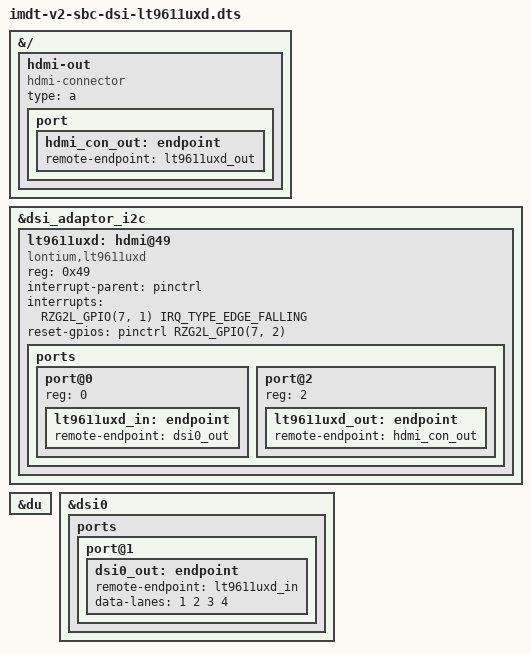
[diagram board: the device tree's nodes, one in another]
/dts-v1/;
/plugin/;

#include <dt-bindings/interrupt-controller/arm-gic.h>
#include <dt-bindings/pinctrl/rzg2l-pinctrl.h>
#include <dt-bindings/gpio/gpio.h>

&{/} {
	hdmi-out {
		compatible = "hdmi-connector";
		type = "a";

		port {
			hdmi_con_out: endpoint {
				remote-endpoint = <&lt9611uxd_out>;
			};
		};
	};
};

&dsi_adaptor_i2c {
	status = "okay";
	#address-cells = <1>;
	#size-cells = <0>;

	lt9611uxd: hdmi@49 {
		compatible = "lontium,lt9611uxd";
		reg = <0x49>;
		interrupt-parent = <&pinctrl>;
		interrupts = <RZG2L_GPIO(7, 1) IRQ_TYPE_EDGE_FALLING>;
		reset-gpios = <&pinctrl RZG2L_GPIO(7, 2) GPIO_ACTIVE_HIGH>;

		ports {
			#address-cells = <1>;
			#size-cells = <0>;

			port@0 {
				reg = <0>;
				lt9611uxd_in: endpoint {
					remote-endpoint = <&dsi0_out>;
				};
			};

			port@2 {
				reg = <2>;
				lt9611uxd_out: endpoint {
					remote-endpoint = <&hdmi_con_out>;
				};
			};
		};
	};
};

&du {
	status = "okay";
};

&dsi0 {
	status = "okay";
	ports {
		port@1 {
			dsi0_out: endpoint {
				remote-endpoint = <&lt9611uxd_in>;
				data-lanes = <1 2 3 4>;
			};
		};
	};
};
